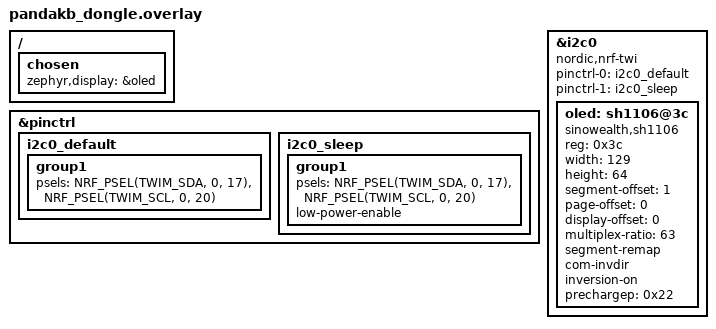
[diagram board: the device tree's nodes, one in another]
/*
 * PandaKB ZMK dongle: nice!nano v2 + 1.3" SH1106 OLED on I2C (SDA P0.17,
 * SCL P0.20, address 0x3C).
 *
 * The panel parameters are copied verbatim from PandaKB's own dongle firmware
 * (github.com/PandaKBLab/zmk-corne-j-dongle). Several are quirks of this
 * specific panel -- notably width = <129> with segment-offset = <1> rather than
 * the usual 128 / 2 for a 1.3" SH1106 -- so they are deliberately left as
 * PandaKB ships them.
 */

/ {
    chosen {
        zephyr,display = &oled;
    };
};

&pinctrl {
    i2c0_default: i2c0_default {
        group1 {
            psels = <NRF_PSEL(TWIM_SDA, 0, 17)>,
                    <NRF_PSEL(TWIM_SCL, 0, 20)>;
        };
    };

    i2c0_sleep: i2c0_sleep {
        group1 {
            psels = <NRF_PSEL(TWIM_SDA, 0, 17)>,
                    <NRF_PSEL(TWIM_SCL, 0, 20)>;
            low-power-enable;
        };
    };
};

&i2c0 {
    status = "okay";
    compatible = "nordic,nrf-twi";
    pinctrl-0 = <&i2c0_default>;
    pinctrl-1 = <&i2c0_sleep>;
    pinctrl-names = "default", "sleep";

    oled: sh1106@3c {
        compatible = "sinowealth,sh1106";
        reg = <0x3c>;
        width = <129>;
        height = <64>;
        segment-offset = <1>;
        page-offset = <0>;
        display-offset = <0>;
        multiplex-ratio = <63>;
        segment-remap;
        com-invdir;
        inversion-on;
        prechargep = <0x22>;
    };
};
